VERSION "1.0 value tables"

NS_ :

BS_:

BU_: BCM DASH

VAL_TABLE_ OnOff 1 "On" 0 "Off" ;
VAL_TABLE_ GearLever 4 "Drive" 3 "Neutral" 2 "Reverse" 1 "Park" 0 "Unknown" ;
VAL_TABLE_ Faults 3 "PermanentFault" 2 "IntermittentFault" 1 "NoFault" 0 "NotAvailable" ;

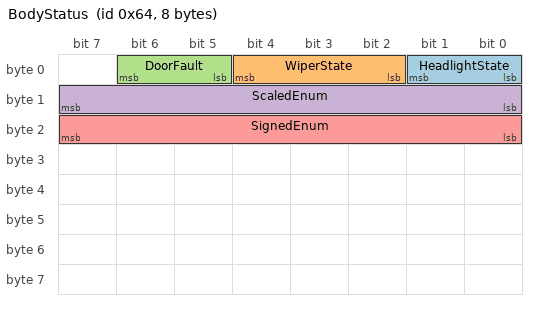
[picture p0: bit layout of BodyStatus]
BO_ 100 BodyStatus: 8 BCM
 SG_ HeadlightState : 0|2@1+ (1,0) [0|3] "" DASH
 SG_ WiperState : 2|3@1+ (1,0) [0|7] "" DASH
 SG_ DoorFault : 5|2@1+ (1,0) [0|3] "" DASH
 SG_ ScaledEnum : 8|8@1+ (2,0) [0|510] "" DASH
 SG_ SignedEnum : 16|8@1- (1,0) [-128|127] "" DASH

CM_ SG_ 100 DoorFault "Uses the shared Faults table values";
VAL_ 100 HeadlightState 0 "Off" 1 "Parking" 2 "LowBeam" 3 "HighBeam" ;
VAL_ 100 WiperState 0 "Off" 1 "Intermittent" 2 "Low" 3 "High" 7 "Invalid" ;
VAL_ 100 DoorFault 0 "NotAvailable" 1 "NoFault" 2 "IntermittentFault" 3 "PermanentFault" ;
VAL_ 100 ScaledEnum 2 "TwoRaw" 4 "FourRaw" ;
VAL_ 100 SignedEnum -1 "MinusOne" -128 "Floor" 0 "Zero" ;
